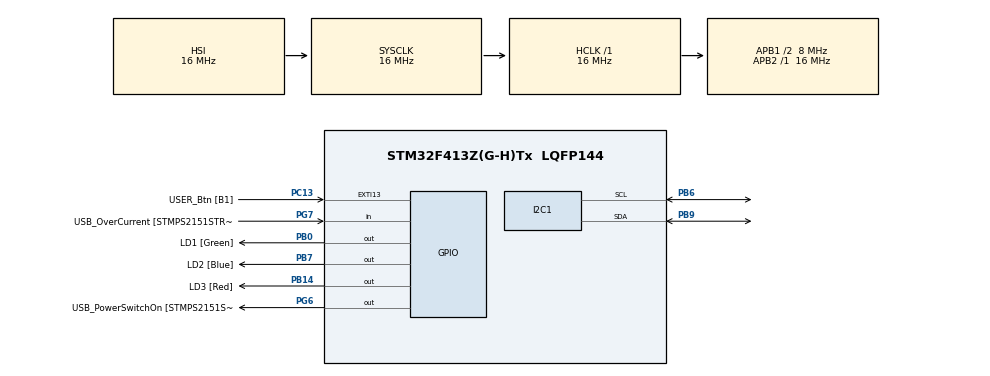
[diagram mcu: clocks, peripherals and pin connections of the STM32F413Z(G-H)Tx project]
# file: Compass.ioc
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Mcu.Family=STM32F4
Mcu.Name=STM32F413Z(G-H)Tx
Mcu.Package=LQFP144
NVIC.PriorityGroup=NVIC_PRIORITYGROUP_4
PA10.GPIO_Label=USB_ID
PA10.Signal=USB_OTG_FS_ID
PA11.GPIO_Label=USB_DM
PA11.Signal=USB_OTG_FS_DM
PA12.GPIO_Label=USB_DP
PA12.Signal=USB_OTG_FS_DP
PA13.GPIO_Label=TMS
PA13.Mode=Trace_Asynchronous_SW
PA13.Signal=SYS_JTMS-SWDIO
PA14.GPIO_Label=TCK
PA14.Mode=Trace_Asynchronous_SW
PA14.Signal=SYS_JTCK-SWCLK
PA8.GPIO_Label=USB_SOF [TP1]
PA8.Signal=USB_OTG_FS_SOF
PA9.GPIO_Label=USB_VBUS
PA9.Signal=USB_OTG_FS_VBUS
PB0.GPIO_Label=LD1 [Green]
PB0.Signal=GPIO_Output
PB14.GPIO_Label=LD3 [Red]
PB14.Signal=GPIO_Output
PB3.GPIO_Label=SWO
PB3.Mode=Trace_Asynchronous_SW
PB3.Signal=SYS_JTDO-SWO
PB6.Mode=I2C
PB6.Signal=I2C1_SCL
PB7.GPIO_Label=LD2 [Blue]
PB7.Signal=GPIO_Output
PB9.Mode=I2C
PB9.Signal=I2C1_SDA
PC13.GPIO_Label=USER_Btn [B1]
PC13.Signal=GPXTI13
PC14-OSC32_IN.Signal=RCC_OSC32_IN
PC15-OSC32_OUT.Signal=RCC_OSC32_OUT
PD8.GPIO_Label=STLK_RX [STM32F103CBT6_PA3]
PD8.Signal=USART3_TX
PD9.GPIO_Label=STLK_TX [STM32F103CBT6_PA2]
PD9.Signal=USART3_RX
PG6.GPIO_Label=USB_PowerSwitchOn [STMPS2151STR_EN]
PG6.Signal=GPIO_Output
PG7.GPIO_Label=USB_OverCurrent [STMPS2151STR_FAULT]
PG7.Signal=GPIO_Input
PH0\ -\ OSC_IN.GPIO_Label=MCO
PH0\ -\ OSC_IN.Signal=RCC_OSC_IN
PH1\ -\ OSC_OUT.Signal=RCC_OSC_OUT
ProjectManager.HeapSize=0x200
ProjectManager.StackSize=0x400
ProjectManager.TargetToolchain=MDK-ARM V5
RCC.48MHZClocksFreq_Value=24000000
RCC.AHBFreq_Value=16000000
RCC.APB1CLKDivider=RCC_HCLK_DIV2
RCC.APB1Freq_Value=8000000
RCC.APB1TimFreq_Value=16000000
RCC.APB2Freq_Value=16000000
RCC.APB2TimFreq_Value=16000000
RCC.CortexFreq_Value=16000000
RCC.HCLKFreq_Value=16000000
RCC.HSE_VALUE=8000000
RCC.HSI_VALUE=16000000
RCC.PLLMUL=RCC_PLL_MUL9
RCC.PRESCALERUSB=RCC_USBCLKSOURCE_PLL_DIV1_5
RCC.SYSCLKFreq_VALUE=16000000
RCC.SYSCLKSourceVirtual=RCC_SYSCLKSOURCE_PLLCLK
RCC.USBFreq_Value=96000000
RCC.VCOOutputFreq_Value=192000000
board=NUCLEO-F413ZH

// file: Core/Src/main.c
/* USER CODE BEGIN Header */
/**
  ******************************************************************************
  * @file           : main.c
  * @brief          : Main program body
  ******************************************************************************
  * @attention
  *
  * <h2><center>&copy; Copyright (c) 2022 STMicroelectronics.
  * All rights reserved.</center></h2>
  *
  * This software component is licensed by ST under BSD 3-Clause license,
  * the "License"; You may not use this file except in compliance with the
  * License. You may obtain a copy of the License at:
  *                        opensource.org/licenses/BSD-3-Clause
  *
  ******************************************************************************
  */
/* USER CODE END Header */
#include "main.h"

I2C_HandleTypeDef hi2c1;

/* USER CODE BEGIN PV */
uint8_t cReg1[2] = {0x00, 0x70};
uint8_t cReg2[2] = {0x01, 0xA0};
uint8_t cReg3[2] = {0x02, 0x00};
uint8_t data[6];
uint8_t adress[2] = {0x06, 0x03};
/* USER CODE END PV */

void SystemClock_Config(void);
static void MX_GPIO_Init(void);
static void MX_I2C1_Init(void);

int main(void)
{

  /* MCU Configuration--------------------------------------------------------*/

  /* Reset of all peripherals, Initializes the Flash interface and the Systick. */
  HAL_Init();

  /* Configure the system clock */
  SystemClock_Config();

  /* Initialize all configured peripherals */
  MX_GPIO_Init();
  MX_I2C1_Init();
  /* USER CODE BEGIN 2 */
	if(HAL_I2C_IsDeviceReady(&hi2c1, 0x3C, 1, 10) == HAL_OK)
	{
		HAL_GPIO_TogglePin(GPIOB, GPIO_PIN_7);
	}
HAL_I2C_Master_Transmit(&hi2c1, 0x3C, cReg1, 2, 10);
HAL_I2C_Master_Transmit(&hi2c1, 0x3C, cReg2, 2, 10);
HAL_I2C_Master_Transmit(&hi2c1, 0x3C, cReg3, 2, 10);
HAL_Delay(6);
  /* USER CODE END 2 */

  /* Infinite loop */
  /* USER CODE BEGIN WHILE */
  while (1)
  {
		HAL_I2C_Master_Transmit(&hi2c1, 0x3C, adress, 1, 10);
		HAL_I2C_Master_Receive(&hi2c1, 0x3C, data, 6, 10);
		//HAL_I2C_Master_Transmit(&hi2c1, 0x3C, &adress[1], 1, 10);
		HAL_Delay(67);
    /* USER CODE END WHILE */

  }
}

void SystemClock_Config(void)
{
  RCC_OscInitTypeDef RCC_OscInitStruct = {0};
  RCC_ClkInitTypeDef RCC_ClkInitStruct = {0};

  /** Configure the main internal regulator output voltage
  */
  __HAL_RCC_PWR_CLK_ENABLE();
  __HAL_PWR_VOLTAGESCALING_CONFIG(PWR_REGULATOR_VOLTAGE_SCALE1);
  /** Initializes the RCC Oscillators according to the specified parameters
  * in the RCC_OscInitTypeDef structure.
  */
  RCC_OscInitStruct.OscillatorType = RCC_OSCILLATORTYPE_HSI;
  RCC_OscInitStruct.HSIState = RCC_HSI_ON;
  RCC_OscInitStruct.HSICalibrationValue = RCC_HSICALIBRATION_DEFAULT;
  RCC_OscInitStruct.PLL.PLLState = RCC_PLL_NONE;
  if (HAL_RCC_OscConfig(&RCC_OscInitStruct) != HAL_OK)
  {
    Error_Handler();
  }
  /** Initializes the CPU, AHB and APB buses clocks
  */
  RCC_ClkInitStruct.ClockType = RCC_CLOCKTYPE_HCLK|RCC_CLOCKTYPE_SYSCLK
                              |RCC_CLOCKTYPE_PCLK1|RCC_CLOCKTYPE_PCLK2;
  RCC_ClkInitStruct.SYSCLKSource = RCC_SYSCLKSOURCE_HSI;
  RCC_ClkInitStruct.AHBCLKDivider = RCC_SYSCLK_DIV1;
  RCC_ClkInitStruct.APB1CLKDivider = RCC_HCLK_DIV2;
  RCC_ClkInitStruct.APB2CLKDivider = RCC_HCLK_DIV1;

  if (HAL_RCC_ClockConfig(&RCC_ClkInitStruct, FLASH_LATENCY_0) != HAL_OK)
  {
    Error_Handler();
  }
}

static void MX_I2C1_Init(void)
{

  hi2c1.Instance = I2C1;
  hi2c1.Init.ClockSpeed = 100000;
  hi2c1.Init.DutyCycle = I2C_DUTYCYCLE_2;
  hi2c1.Init.OwnAddress1 = 0;
  hi2c1.Init.AddressingMode = I2C_ADDRESSINGMODE_7BIT;
  hi2c1.Init.DualAddressMode = I2C_DUALADDRESS_DISABLE;
  hi2c1.Init.OwnAddress2 = 0;
  hi2c1.Init.GeneralCallMode = I2C_GENERALCALL_DISABLE;
  hi2c1.Init.NoStretchMode = I2C_NOSTRETCH_DISABLE;
  if (HAL_I2C_Init(&hi2c1) != HAL_OK)
  {
    Error_Handler();
  }

}

static void MX_GPIO_Init(void)
{
  GPIO_InitTypeDef GPIO_InitStruct = {0};

  /* GPIO Ports Clock Enable */
  __HAL_RCC_GPIOC_CLK_ENABLE();
  __HAL_RCC_GPIOH_CLK_ENABLE();
  __HAL_RCC_GPIOB_CLK_ENABLE();
  __HAL_RCC_GPIOD_CLK_ENABLE();
  __HAL_RCC_GPIOG_CLK_ENABLE();
  __HAL_RCC_GPIOA_CLK_ENABLE();

  /*Configure GPIO pin Output Level */
  HAL_GPIO_WritePin(GPIOB, LD1_Pin|LD3_Pin|LD2_Pin, GPIO_PIN_RESET);

  /*Configure GPIO pin Output Level */
  HAL_GPIO_WritePin(USB_PowerSwitchOn_GPIO_Port, USB_PowerSwitchOn_Pin, GPIO_PIN_RESET);

  /*Configure GPIO pin : USER_Btn_Pin */
  GPIO_InitStruct.Pin = USER_Btn_Pin;
  GPIO_InitStruct.Mode = GPIO_MODE_IT_RISING;
  GPIO_InitStruct.Pull = GPIO_NOPULL;
  HAL_GPIO_Init(USER_Btn_GPIO_Port, &GPIO_InitStruct);

  /*Configure GPIO pins : LD1_Pin LD3_Pin LD2_Pin */
  GPIO_InitStruct.Pin = LD1_Pin|LD3_Pin|LD2_Pin;
  GPIO_InitStruct.Mode = GPIO_MODE_OUTPUT_PP;
  GPIO_InitStruct.Pull = GPIO_NOPULL;
  GPIO_InitStruct.Speed = GPIO_SPEED_FREQ_LOW;
  HAL_GPIO_Init(GPIOB, &GPIO_InitStruct);

  /*Configure GPIO pins : STLK_RX_Pin STLK_TX_Pin */
  GPIO_InitStruct.Pin = STLK_RX_Pin|STLK_TX_Pin;
  GPIO_InitStruct.Mode = GPIO_MODE_AF_PP;
  GPIO_InitStruct.Pull = GPIO_NOPULL;
  GPIO_InitStruct.Speed = GPIO_SPEED_FREQ_VERY_HIGH;
  GPIO_InitStruct.Alternate = GPIO_AF7_USART3;
  HAL_GPIO_Init(GPIOD, &GPIO_InitStruct);

  /*Configure GPIO pin : USB_PowerSwitchOn_Pin */
  GPIO_InitStruct.Pin = USB_PowerSwitchOn_Pin;
  GPIO_InitStruct.Mode = GPIO_MODE_OUTPUT_PP;
  GPIO_InitStruct.Pull = GPIO_NOPULL;
  GPIO_InitStruct.Speed = GPIO_SPEED_FREQ_LOW;
  HAL_GPIO_Init(USB_PowerSwitchOn_GPIO_Port, &GPIO_InitStruct);

  /*Configure GPIO pin : USB_OverCurrent_Pin */
  GPIO_InitStruct.Pin = USB_OverCurrent_Pin;
  GPIO_InitStruct.Mode = GPIO_MODE_INPUT;
  GPIO_InitStruct.Pull = GPIO_NOPULL;
  HAL_GPIO_Init(USB_OverCurrent_GPIO_Port, &GPIO_InitStruct);

  /*Configure GPIO pins : USB_SOF_Pin USB_ID_Pin USB_DM_Pin USB_DP_Pin */
  GPIO_InitStruct.Pin = USB_SOF_Pin|USB_ID_Pin|USB_DM_Pin|USB_DP_Pin;
  GPIO_InitStruct.Mode = GPIO_MODE_AF_PP;
  GPIO_InitStruct.Pull = GPIO_NOPULL;
  GPIO_InitStruct.Speed = GPIO_SPEED_FREQ_VERY_HIGH;
  GPIO_InitStruct.Alternate = GPIO_AF10_OTG_FS;
  HAL_GPIO_Init(GPIOA, &GPIO_InitStruct);

}

void Error_Handler(void)
{
  __disable_irq();
  while (1)
  {
  }
}

/************************ (C) COPYRIGHT STMicroelectronics *****END OF FILE****/
